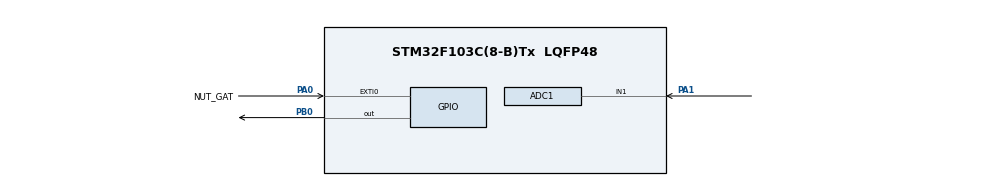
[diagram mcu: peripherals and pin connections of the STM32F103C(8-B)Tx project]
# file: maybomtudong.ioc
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ADC1.Channel-4\#ChannelRegularConversion=ADC_CHANNEL_1
ADC1.NbrOfConversionFlag=1
ADC1.Rank-4\#ChannelRegularConversion=1
ADC1.SamplingTime-4\#ChannelRegularConversion=ADC_SAMPLETIME_1CYCLE_5
ADC1.master=1
Mcu.Family=STM32F1
Mcu.Name=STM32F103C(8-B)Tx
Mcu.Package=LQFP48
NVIC.EXTI0_IRQn=true\:0\:0\:false\:false\:true\:true\:true\:true
NVIC.PriorityGroup=NVIC_PRIORITYGROUP_4
PA0-WKUP.GPIO_Label=NUT_GAT
PA0-WKUP.GPIO_PuPd=GPIO_PULLUP
PA0-WKUP.Signal=GPXTI0
PA1.Signal=ADCx_IN1
PB0.Signal=GPIO_Output
ProjectManager.HeapSize=0x200
ProjectManager.StackSize=0x400
ProjectManager.TargetToolchain=STM32CubeIDE
RCC.APB1Freq_Value=8000000
RCC.APB2Freq_Value=8000000
SH.ADCx_IN1.0=ADC1_IN1,IN1
TIM1.Prescaler=8-1
VP_SYS_VS_ND.Mode=No_Debug
VP_TIM1_VS_ClockSourceINT.Mode=Internal
board=custom

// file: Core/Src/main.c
/* USER CODE BEGIN Header */
/**
  ******************************************************************************
  * @file           : main.c
  * @brief          : Main program body
  ******************************************************************************
  * @attention
  *
  * Copyright (c) 2026 STMicroelectronics.
  * All rights reserved.
  *
  * This software is licensed under terms that can be found in the LICENSE file
  * in the root directory of this software component.
  * If no LICENSE file comes with this software, it is provided AS-IS.
  *
  ******************************************************************************
  */
/* USER CODE END Header */
#include "main.h"

ADC_HandleTypeDef hadc1;

TIM_HandleTypeDef htim1;

/* USER CODE BEGIN PV */
uint32_t water_val = 0; // Khai báo biến lưu giá trị ADC
volatile uint8_t system_off = 0; // 1 là ngắt bơm, 0 là chạy tự động

const uint32_t NGUONG_DAY = 3500;
const uint32_t NGUONG_CAN = 1500;
/* USER CODE END PV */

void SystemClock_Config(void);
static void MX_GPIO_Init(void);
static void MX_ADC1_Init(void);
static void MX_TIM1_Init(void);
/* USER CODE BEGIN PFP */
void delay_us(uint16_t us);
/* USER CODE END PFP */

int main(void)
{

  /* MCU Configuration--------------------------------------------------------*/

  /* Reset of all peripherals, Initializes the Flash interface and the Systick. */
  HAL_Init();

  /* Configure the system clock */
  SystemClock_Config();

  /* Initialize all configured peripherals */
  MX_GPIO_Init();
  MX_ADC1_Init();
  MX_TIM1_Init();
  /* USER CODE BEGIN 2 */
  HAL_TIM_Base_Start(&htim1);
  /* USER CODE END 2 */

  /* Infinite loop */
  while (1)
  {
	  // 1. KIỂM TRA BIẾN CỜ (Do Ngắt ngoài EXTI điều khiển)
	        if (system_off == 1)
	        {
	            // Nếu đang ở chế độ OFF, đảm bảo bơm luôn TẮT

	            HAL_GPIO_WritePin(GPIOB, GPIO_PIN_0, GPIO_PIN_RESET);
	            HAL_GPIO_WritePin(GPIOC, GPIO_PIN_13, GPIO_PIN_SET); // LED board tắt

	            HAL_Delay(100);
	            continue; // Nhảy ngược lại đầu while, bỏ qua phần đọc ADC bên dưới
	        }

	        // 2. CHẾ ĐỘ TỰ ĐỘNG (Chỉ chạy khi system_off == 0)
	        HAL_ADC_Start(&hadc1);
	        if (HAL_ADC_PollForConversion(&hadc1, 10) == HAL_OK)
	        {
	            water_val = HAL_ADC_GetValue(&hadc1);
	        }
	        HAL_ADC_Stop(&hadc1);

	        // Logic điều khiển theo mực nước
	        if (water_val > 3500)
	        {
	            HAL_GPIO_WritePin(GPIOB, GPIO_PIN_0, GPIO_PIN_RESET);
	            HAL_GPIO_WritePin(GPIOC, GPIO_PIN_13, GPIO_PIN_SET);
	        }
	        else if (water_val < 1500)
	        {
	            HAL_GPIO_WritePin(GPIOB, GPIO_PIN_0, GPIO_PIN_SET);
	            HAL_GPIO_WritePin(GPIOC, GPIO_PIN_13, GPIO_PIN_RESET);
	        }

	        HAL_Delay(200);
  }
}

void SystemClock_Config(void)
{
  RCC_OscInitTypeDef RCC_OscInitStruct = {0};
  RCC_ClkInitTypeDef RCC_ClkInitStruct = {0};
  RCC_PeriphCLKInitTypeDef PeriphClkInit = {0};

  /** Initializes the RCC Oscillators according to the specified parameters
  * in the RCC_OscInitTypeDef structure.
  */
  RCC_OscInitStruct.OscillatorType = RCC_OSCILLATORTYPE_HSI;
  RCC_OscInitStruct.HSIState = RCC_HSI_ON;
  RCC_OscInitStruct.HSICalibrationValue = RCC_HSICALIBRATION_DEFAULT;
  RCC_OscInitStruct.PLL.PLLState = RCC_PLL_NONE;
  if (HAL_RCC_OscConfig(&RCC_OscInitStruct) != HAL_OK)
  {
    Error_Handler();
  }

  /** Initializes the CPU, AHB and APB buses clocks
  */
  RCC_ClkInitStruct.ClockType = RCC_CLOCKTYPE_HCLK|RCC_CLOCKTYPE_SYSCLK
                              |RCC_CLOCKTYPE_PCLK1|RCC_CLOCKTYPE_PCLK2;
  RCC_ClkInitStruct.SYSCLKSource = RCC_SYSCLKSOURCE_HSI;
  RCC_ClkInitStruct.AHBCLKDivider = RCC_SYSCLK_DIV1;
  RCC_ClkInitStruct.APB1CLKDivider = RCC_HCLK_DIV1;
  RCC_ClkInitStruct.APB2CLKDivider = RCC_HCLK_DIV1;

  if (HAL_RCC_ClockConfig(&RCC_ClkInitStruct, FLASH_LATENCY_0) != HAL_OK)
  {
    Error_Handler();
  }
  PeriphClkInit.PeriphClockSelection = RCC_PERIPHCLK_ADC;
  PeriphClkInit.AdcClockSelection = RCC_ADCPCLK2_DIV2;
  if (HAL_RCCEx_PeriphCLKConfig(&PeriphClkInit) != HAL_OK)
  {
    Error_Handler();
  }
}

static void MX_ADC1_Init(void)
{

  ADC_ChannelConfTypeDef sConfig = {0};

  /** Common config
  */
  hadc1.Instance = ADC1;
  hadc1.Init.ScanConvMode = ADC_SCAN_DISABLE;
  hadc1.Init.ContinuousConvMode = DISABLE;
  hadc1.Init.DiscontinuousConvMode = DISABLE;
  hadc1.Init.ExternalTrigConv = ADC_SOFTWARE_START;
  hadc1.Init.DataAlign = ADC_DATAALIGN_RIGHT;
  hadc1.Init.NbrOfConversion = 1;
  if (HAL_ADC_Init(&hadc1) != HAL_OK)
  {
    Error_Handler();
  }

  /** Configure Regular Channel
  */
  sConfig.Channel = ADC_CHANNEL_1;
  sConfig.Rank = ADC_REGULAR_RANK_1;
  sConfig.SamplingTime = ADC_SAMPLETIME_1CYCLE_5;
  if (HAL_ADC_ConfigChannel(&hadc1, &sConfig) != HAL_OK)
  {
    Error_Handler();
  }

}

static void MX_TIM1_Init(void)
{

  TIM_ClockConfigTypeDef sClockSourceConfig = {0};
  TIM_MasterConfigTypeDef sMasterConfig = {0};

  htim1.Instance = TIM1;
  htim1.Init.Prescaler = 8-1;
  htim1.Init.CounterMode = TIM_COUNTERMODE_UP;
  htim1.Init.Period = 65535;
  htim1.Init.ClockDivision = TIM_CLOCKDIVISION_DIV1;
  htim1.Init.RepetitionCounter = 0;
  htim1.Init.AutoReloadPreload = TIM_AUTORELOAD_PRELOAD_DISABLE;
  if (HAL_TIM_Base_Init(&htim1) != HAL_OK)
  {
    Error_Handler();
  }
  sClockSourceConfig.ClockSource = TIM_CLOCKSOURCE_INTERNAL;
  if (HAL_TIM_ConfigClockSource(&htim1, &sClockSourceConfig) != HAL_OK)
  {
    Error_Handler();
  }
  sMasterConfig.MasterOutputTrigger = TIM_TRGO_RESET;
  sMasterConfig.MasterSlaveMode = TIM_MASTERSLAVEMODE_DISABLE;
  if (HAL_TIMEx_MasterConfigSynchronization(&htim1, &sMasterConfig) != HAL_OK)
  {
    Error_Handler();
  }

}

static void MX_GPIO_Init(void)
{
  GPIO_InitTypeDef GPIO_InitStruct = {0};

  /* GPIO Ports Clock Enable */
  __HAL_RCC_GPIOA_CLK_ENABLE();
  __HAL_RCC_GPIOB_CLK_ENABLE();

  /*Configure GPIO pin Output Level */
  HAL_GPIO_WritePin(GPIOB, GPIO_PIN_0, GPIO_PIN_RESET);

  /*Configure GPIO pin : NUT_GAT_Pin */
  GPIO_InitStruct.Pin = NUT_GAT_Pin;
  GPIO_InitStruct.Mode = GPIO_MODE_IT_RISING;
  GPIO_InitStruct.Pull = GPIO_PULLUP;
  HAL_GPIO_Init(NUT_GAT_GPIO_Port, &GPIO_InitStruct);

  /*Configure GPIO pin : PB0 */
  GPIO_InitStruct.Pin = GPIO_PIN_0;
  GPIO_InitStruct.Mode = GPIO_MODE_OUTPUT_PP;
  GPIO_InitStruct.Pull = GPIO_NOPULL;
  GPIO_InitStruct.Speed = GPIO_SPEED_FREQ_LOW;
  HAL_GPIO_Init(GPIOB, &GPIO_InitStruct);

  /* EXTI interrupt init*/
  HAL_NVIC_SetPriority(EXTI0_IRQn, 0, 0);
  HAL_NVIC_EnableIRQ(EXTI0_IRQn);

}

/* USER CODE BEGIN 4 */
void HAL_GPIO_EXTI_Callback(uint16_t GPIO_Pin)
{
    if(GPIO_Pin == GPIO_PIN_0) // Nếu là ngắt từ chân PA0
    {
        // Đọc trạng thái nút gạt: Nếu chân PA0 bị nối xuống GND (RESET)
        if(HAL_GPIO_ReadPin(GPIOA, GPIO_PIN_0) == GPIO_PIN_RESET)
        {
            system_off = 1; // Khóa hệ thống
            HAL_GPIO_WritePin(GPIOB, GPIO_PIN_0, GPIO_PIN_SET);   // ÉP TẮT BƠM NGAY
            HAL_GPIO_WritePin(GPIOC, GPIO_PIN_13, GPIO_PIN_SET); // Tắt LED board
        }
        else // Nếu gạt ngược lại (SET)
        {
            system_off = 0; // Mở khóa cho chạy tự động
        }
    }
}
/* USER CODE END 4 */

void Error_Handler(void)
{
  __disable_irq();
  while (1)
  {
  }
}
